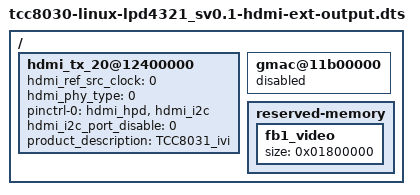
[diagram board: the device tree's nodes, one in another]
// SPDX-License-Identifier: (GPL-2.0-or-later OR MIT)
/*
 * Copyright (C) Telechips Inc.
 */

#include "tcc8030-linux-lpd4321_sv0.1.dts"

/ {
	/* hdmi override. */
	hdmi_tx_20@12400000 {
		status = "okay";
		hdmi_ref_src_clock = <0>; // 0 XIN, 1 X-TAL, 2 PERI, 3, PMU XIN
		hdmi_phy_type = <0>; // 0 8031

		/* Pinctrl and gpio */
		pinctrl-0 = <&hdmi_hpd &hdmi_i2c>;

		/* DDC */
		hdmi_i2c_port_disable = <0>;

		/* Source Product Description */
		product_description = "TCC8031_ivi";
	};

	/* gmac
	 * gmac1_rxer	: gpc-14
	 * gmac1_rxdv	: gpc-8
	 * gmac1_txer	: gpc-15
	 */
	gmac@11b00000 {
		status = "disable";
	};

	/* uart7_rtscts	: gpc-8, gpc-9 */
	/* i2c14_bus	: gpc-14, gpc-15 */

	/* pmap for frame buffer 1 */
	reserved-memory {
		fb1_video {
			size = <0x01800000>;
		};
	};
};
